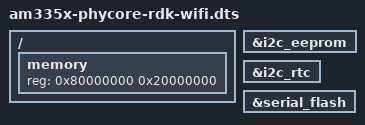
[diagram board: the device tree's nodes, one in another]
/*
 * Copyright (C) 2016 PHYTEC Messtechnik GmbH,
 * Author: Wadim Egorov <w.egorov@phytec.de>
 *
 * This program is free software; you can redistribute it and/or modify
 * it under the terms of the GNU General Public License version 2 as
 * published by the Free Software Foundation.
 */

/dts-v1/;

#include "am335x-phycore-som.dtsi"
#include "am335x-pcm-953-wifi.dtsi"
#include "am335x-pcm-958.dtsi"

/ {
	memory {
		device_type = "memory";
		reg = <0x80000000 0x20000000>; /* 512 MB */
	};
};

/* SoM */
&i2c_eeprom {
	status = "okay";
};

&i2c_rtc {
	status = "okay";
};

&serial_flash {
	status = "okay";
};
